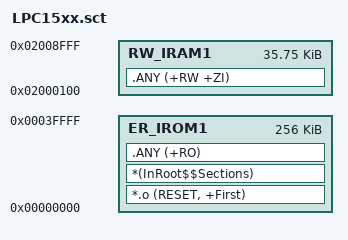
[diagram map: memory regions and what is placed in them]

LR_IROM1 0x00000000 0x40000  {    ; load region size_region (256k)
  ER_IROM1 0x00000000 0x40000  {  ; load address = execution address
   *.o (RESET, +First)
   *(InRoot$$Sections)
   .ANY (+RO)
  }
  ; 8_byte_aligned(16+47 vect * 4 bytes) = 0x100
  ; 36kB(0x9000) - 0x100 = 0x8F00
  RW_IRAM1 (0x02000000+0x100) (0x9000-0x100)  {
   .ANY (+RW +ZI)
  }
}
